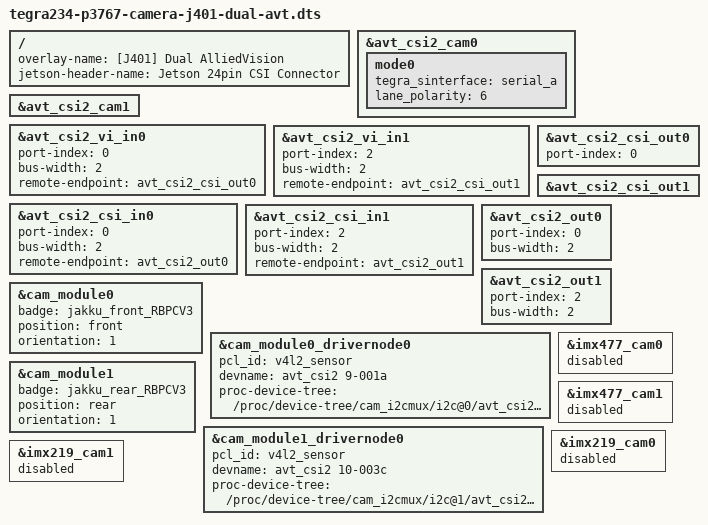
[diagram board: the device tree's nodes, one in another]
// SPDX-License-Identifier: GPL-2.0-only
/*
 * Jetson Device-tree overlay for 
 *		* Allied Vision cameras on both J12 and J9 
 * on the Seeed Studio J401 baseboard
 *
 * Copyright (c) 2021-2023 NVIDIA CORPORATION. All rights reserved.
 *
 */

/dts-v1/;
/plugin/;

#include <dt-common/jetson/tegra234-p3767-0000-common.h>

/ {
	overlay-name = "[J401] Dual AlliedVision";
	jetson-header-name = "Jetson 24pin CSI Connector";
    compatible = JETSON_COMPATIBLE_P3768;

	/* Enable CAM0 */
	fragment@0 {
		target = <&avt_csi2_cam0>;
		__overlay__ {
			status = "okay";

			mode0 {
				tegra_sinterface = "serial_a";
				lane_polarity = "6";
			};
		};
	};

	fragment@1 {
		target = <&avt_csi2_cam1>;
		__overlay__ {
			status = "okay";
		};
	};



	fragment@2 {
		target = <&avt_csi2_vi_in0>;
		__overlay__ {
			status = "okay";
			port-index = <0>;
			bus-width = <2>;
			remote-endpoint = <&avt_csi2_csi_out0>;
		};
	};

	fragment@3 {
		target = <&avt_csi2_vi_in1>;
		__overlay__ {
			status = "okay";
			port-index = <2>;
			bus-width = <2>;
			remote-endpoint = <&avt_csi2_csi_out1>;
		};
	};

	fragment@4 {
		target = <&avt_csi2_csi_in0>;
		__overlay__ {
			status = "okay";
			port-index = <0>;
			bus-width = <2>;
			remote-endpoint = <&avt_csi2_out0>;
		};
	};

	fragment@5 {
		target = <&avt_csi2_csi_in1>;
		__overlay__ {
			status = "okay";
			port-index = <2>;
			bus-width = <2>;
			remote-endpoint = <&avt_csi2_out1>;
		};
	};

	fragment@6 {
		target = <&avt_csi2_csi_out0>;
		__overlay__ {
			status = "okay";
			port-index = <0>;
		};
	};
	fragment@7 {
		target = <&avt_csi2_csi_out1>;
		__overlay__ {
			status = "okay";
		};
	};

	fragment@8 {
		target = <&avt_csi2_out0>;
		__overlay__ {
			port-index = <0>;
			bus-width = <2>;
		};
	};

	fragment@9 {
		target = <&avt_csi2_out1>;
		__overlay__ {
			port-index = <2>;
			bus-width = <2>;
		};
	};



	fragment@10 {
		target = <&cam_module0>;
		__overlay__ {
			status = "okay";
			badge = "jakku_front_RBPCV3";
			position = "front";
			orientation = "1";
		};
	};
	fragment@11 {
		target = <&cam_module0_drivernode0>;
		__overlay__ {
			status = "okay";
			pcl_id = "v4l2_sensor";
			devname = "avt_csi2 9-001a";
			proc-device-tree = "/proc/device-tree/cam_i2cmux/i2c@0/avt_csi2_cam0@3c";
		};
	};

	fragment@12 {
		target = <&cam_module1>;
		__overlay__ {
			status = "okay";
			badge = "jakku_rear_RBPCV3";
			position = "rear";
			orientation = "1";
		};
	};
	fragment@13 {
		target = <&cam_module1_drivernode0>;
		__overlay__ {
			status = "okay";
			pcl_id = "v4l2_sensor";
			devname = "avt_csi2 10-003c";
			proc-device-tree = "/proc/device-tree/cam_i2cmux/i2c@1/avt_csi2_cam1@3c";
		};
	};

	/* Disable IMX477 */
	fragment@14 {
		target = <&imx477_cam0>;
		__overlay__ {
			status = "disabled";
		};
	};

	fragment@15 {
		target = <&imx477_cam1>;
		__overlay__ {
			status = "disabled";
		};
	};

	/* Disable IMX219 */
	fragment@16 {
		target = <&imx219_cam0>;
		__overlay__ {
			status = "disabled";
		};
	};

	fragment@17 {
		target = <&imx219_cam1>;
		__overlay__ {
			status = "disabled";
		};
	};
};
